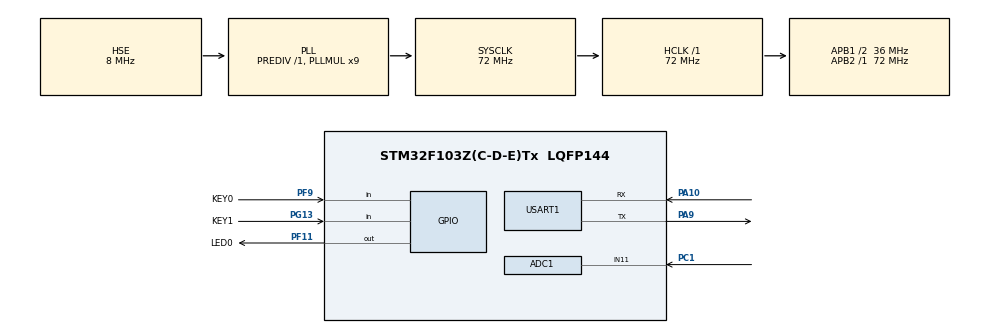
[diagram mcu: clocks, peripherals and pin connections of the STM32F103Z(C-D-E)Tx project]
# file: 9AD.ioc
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ADC1.Channel-7\#ChannelRegularConversion=ADC_CHANNEL_11
ADC1.ContinuousConvMode=ENABLE
ADC1.NbrOfConversionFlag=1
ADC1.Rank-7\#ChannelRegularConversion=1
ADC1.SamplingTime-7\#ChannelRegularConversion=ADC_SAMPLETIME_1CYCLE_5
ADC1.master=1
Mcu.Family=STM32F1
Mcu.Name=STM32F103Z(C-D-E)Tx
Mcu.Package=LQFP144
NVIC.ADC1_2_IRQn=true\:0\:0\:false\:false\:true\:true\:true
NVIC.PriorityGroup=NVIC_PRIORITYGROUP_4
OSC_IN.Mode=HSE-External-Oscillator
OSC_IN.Signal=RCC_OSC_IN
OSC_OUT.Mode=HSE-External-Oscillator
OSC_OUT.Signal=RCC_OSC_OUT
PA10.Mode=Asynchronous
PA10.Signal=USART1_RX
PA13.Mode=Serial_Wire
PA13.Signal=SYS_JTMS-SWDIO
PA14.Mode=Serial_Wire
PA14.Signal=SYS_JTCK-SWCLK
PA9.Mode=Asynchronous
PA9.Signal=USART1_TX
PC1.Signal=ADCx_IN11
PC14-OSC32_IN.Mode=LSE-External-Oscillator
PC14-OSC32_IN.Signal=RCC_OSC32_IN
PC15-OSC32_OUT.Mode=LSE-External-Oscillator
PC15-OSC32_OUT.Signal=RCC_OSC32_OUT
PF11.GPIO_Label=LED0
PF11.Signal=GPIO_Output
PF9.GPIO_Label=KEY0
PF9.GPIO_PuPd=GPIO_PULLUP
PF9.Signal=GPIO_Input
PG13.GPIO_Label=KEY1
PG13.GPIO_PuPd=GPIO_PULLUP
PG13.Signal=GPIO_Input
ProjectManager.HeapSize=0x200
ProjectManager.StackSize=0x400
ProjectManager.TargetToolchain=MDK-ARM V5.27
RCC.ADCPresc=RCC_ADCPCLK2_DIV6
RCC.AHBFreq_Value=72000000
RCC.APB1CLKDivider=RCC_HCLK_DIV2
RCC.APB1Freq_Value=36000000
RCC.APB1TimFreq_Value=72000000
RCC.APB2Freq_Value=72000000
RCC.APB2TimFreq_Value=72000000
RCC.HCLKFreq_Value=72000000
RCC.PLLMUL=RCC_PLL_MUL9
RCC.PLLSourceVirtual=RCC_PLLSOURCE_HSE
RCC.SYSCLKFreq_VALUE=72000000
RCC.SYSCLKSource=RCC_SYSCLKSOURCE_PLLCLK
RCC.USBFreq_Value=72000000
SH.ADCx_IN11.0=ADC1_IN11,IN11
USART1.VirtualMode=VM_ASYNC
board=custom

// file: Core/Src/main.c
/* USER CODE BEGIN Header */
/**
  ******************************************************************************
  * @file           : main.c
  * @brief          : Main program body
  ******************************************************************************
  * @attention
  *
  * <h2><center>&copy; Copyright (c) 2021 STMicroelectronics.
  * All rights reserved.</center></h2>
  *
  * This software component is licensed by ST under BSD 3-Clause license,
  * the "License"; You may not use this file except in compliance with the
  * License. You may obtain a copy of the License at:
  *                        opensource.org/licenses/BSD-3-Clause
  *
  ******************************************************************************
  */
/* USER CODE END Header */
#include "main.h"
#include "adc.h"
#include "usart.h"
#include "gpio.h"

/* USER CODE BEGIN Includes */
#include "stdio.h"
/* USER CODE END Includes */

/* USER CODE BEGIN PTD */
uint16_t adc_value;

int fputc(int c, FILE *stream)
{
	HAL_UART_Transmit(&huart1, (unsigned char *)&c, 1, 1000);
	return 1;
}
void HAL_ADC_ConvCpltCallback(ADC_HandleTypeDef* hadc){
	adc_value = HAL_ADC_GetValue(hadc);
}
/* USER CODE END PTD */

void SystemClock_Config(void);

int main(void)
{

  /* MCU Configuration--------------------------------------------------------*/

  /* Reset of all peripherals, Initializes the Flash interface and the Systick. */
  HAL_Init();

  /* Configure the system clock */
  SystemClock_Config();

  /* Initialize all configured peripherals */
  MX_GPIO_Init();
  MX_ADC1_Init();
  MX_USART1_UART_Init();
  /* USER CODE BEGIN 2 */
	HAL_ADC_Start_IT(&hadc1);
  /* USER CODE END 2 */

  /* Infinite loop */
  while (1)
  {
		HAL_GPIO_TogglePin(LED0_GPIO_Port,LED0_Pin);
		printf("%d\r\n",adc_value);
		HAL_Delay(500);
  }
}

void SystemClock_Config(void)
{
  RCC_OscInitTypeDef RCC_OscInitStruct = {0};
  RCC_ClkInitTypeDef RCC_ClkInitStruct = {0};
  RCC_PeriphCLKInitTypeDef PeriphClkInit = {0};

  /** Initializes the RCC Oscillators according to the specified parameters
  * in the RCC_OscInitTypeDef structure.
  */
  RCC_OscInitStruct.OscillatorType = RCC_OSCILLATORTYPE_HSE;
  RCC_OscInitStruct.HSEState = RCC_HSE_ON;
  RCC_OscInitStruct.HSEPredivValue = RCC_HSE_PREDIV_DIV1;
  RCC_OscInitStruct.HSIState = RCC_HSI_ON;
  RCC_OscInitStruct.PLL.PLLState = RCC_PLL_ON;
  RCC_OscInitStruct.PLL.PLLSource = RCC_PLLSOURCE_HSE;
  RCC_OscInitStruct.PLL.PLLMUL = RCC_PLL_MUL9;
  if (HAL_RCC_OscConfig(&RCC_OscInitStruct) != HAL_OK)
  {
    Error_Handler();
  }
  /** Initializes the CPU, AHB and APB buses clocks
  */
  RCC_ClkInitStruct.ClockType = RCC_CLOCKTYPE_HCLK|RCC_CLOCKTYPE_SYSCLK
                              |RCC_CLOCKTYPE_PCLK1|RCC_CLOCKTYPE_PCLK2;
  RCC_ClkInitStruct.SYSCLKSource = RCC_SYSCLKSOURCE_PLLCLK;
  RCC_ClkInitStruct.AHBCLKDivider = RCC_SYSCLK_DIV1;
  RCC_ClkInitStruct.APB1CLKDivider = RCC_HCLK_DIV2;
  RCC_ClkInitStruct.APB2CLKDivider = RCC_HCLK_DIV1;

  if (HAL_RCC_ClockConfig(&RCC_ClkInitStruct, FLASH_LATENCY_2) != HAL_OK)
  {
    Error_Handler();
  }
  PeriphClkInit.PeriphClockSelection = RCC_PERIPHCLK_ADC;
  PeriphClkInit.AdcClockSelection = RCC_ADCPCLK2_DIV6;
  if (HAL_RCCEx_PeriphCLKConfig(&PeriphClkInit) != HAL_OK)
  {
    Error_Handler();
  }
}

void Error_Handler(void)
{
  __disable_irq();
  while (1)
  {
  }
}

/************************ (C) COPYRIGHT STMicroelectronics *****END OF FILE****/
